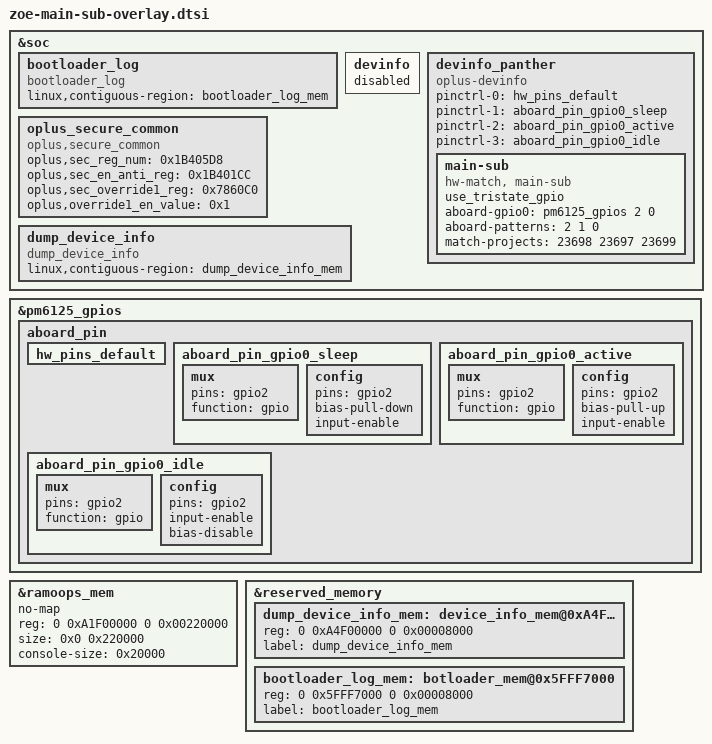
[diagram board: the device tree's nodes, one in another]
&soc {
	bootloader_log {
		compatible = "bootloader_log";
		linux,contiguous-region = <&bootloader_log_mem>;
	};

	devinfo {
		 status = "disabled";
		};
	devinfo_panther {
		compatible = "oplus-devinfo";
		pinctrl-names = "default", "sleep", "active", "idle";
		pinctrl-0 = <&hw_pins_default>;
		pinctrl-1 = <&aboard_pin_gpio0_sleep>;
		pinctrl-2 = <&aboard_pin_gpio0_active>;
		pinctrl-3 = <&aboard_pin_gpio0_idle>;
		main-sub {
			use_tristate_gpio;
			compatible = "hw-match, main-sub";
			aboard-gpio0 = <&pm6125_gpios 2 0>;
			aboard-patterns = <2 1 0>;    /*0[high-resistance] 1[pull-down] 2[pull-up]*/
			/*main board*/
			match-projects = <23698 23697 23699>;
		 };
	};

        // #ifdef OPLUS_FEATURE_SECURITY_COMMON
        /* Ping.Liu@Bsp.Fingerprint.Secure 2019-10-16 add for secure proc */
        oplus_secure_common {
            compatible = "oplus,secure_common";
            oplus,sec_reg_num = <0x1B405D8>;
            oplus,sec_en_anti_reg = <0x1B401CC>;
            oplus,sec_override1_reg = <0x7860C0>;
            oplus,override1_en_value = <0x1>;
        };
         //#endif /* OPLUS_FEATURE_SECURITY_COMMON */

};
&pm6125_gpios {
	aboard_pin {
			hw_pins_default:hw_pins_default {
		};

		aboard_pin_gpio0_sleep:aboard_pin_gpio0_sleep {
			mux {
				pins = "gpio2";
				function = "gpio";
			};
			config {
				pins = "gpio2";
	                        bias-pull-down;
        	                input-enable;
			};
		};
		aboard_pin_gpio0_active:aboard_pin_gpio0_active {
			mux {
				pins = "gpio2";
				function = "gpio";
			};
			config {
				pins = "gpio2";
	                  	bias-pull-up;
                       	 	input-enable;
			};
		};

                aboard_pin_gpio0_idle:aboard_pin_gpio0_idle {
			mux {
				pins = "gpio2";
				function = "gpio";
			};
			config {
				pins = "gpio2";
				input-enable;
				bias-disable;
			};
		};
	};
};

/* OPLUS_FEATURE_DUMP_DEVICE_INFO */
&ramoops_mem {
	no-map;
	reg = <0 0xA1F00000 0 0x00220000>;
	size = <0x0 0x220000>;
	console-size = <0x20000>;
};
&reserved_memory {
	dump_device_info_mem: device_info_mem@0xA4F00000 {
		reg = <0 0xA4F00000 0 0x00008000>;
		label = "dump_device_info_mem";
	};
};
&soc {
	dump_device_info {
		compatible = "dump_device_info";
		linux,contiguous-region = <&dump_device_info_mem>;
	};
};

&reserved_memory {
	/*
	This size is from
	boot_images/QcomPkg/SocPkg/DivarPkg/LAA/uefiplat.cfg
	0x5FFF7000, 0x00008000, "Log Buffer",        AddMem, SYS_MEM, SYS_MEM_CAP, RtData, WRITE_BACK_XN
	so we reserve this for bootloader log
	*/
	bootloader_log_mem: botloader_mem@0x5FFF7000 {
		reg = <0 0x5FFF7000 0 0x00008000>;
		label = "bootloader_log_mem";
	};
};
